# EDGE register map
Registers are 32-bit, access not given, reset 0x11 unless marked. A register's access mark holds for its fields unless they carry their own. Offsets are from the block's base; lines under a group give offsets from that group; [hi:lo] are bit positions; {n}, {i} and the like mark numbered series; 'fields as' and 'values as' point back to an identical list; <NAME> marks a mode.

## Memory map
0x40021000 CTRL size 0x400 — Control & status block
0x40022000 CTRL2 size 0x400
0x40030000 LOOP1
0x40031000 LOOP2

## CTRL — Control & status block
Base 0x40021000
Same registers: CTRL2 0x40022000
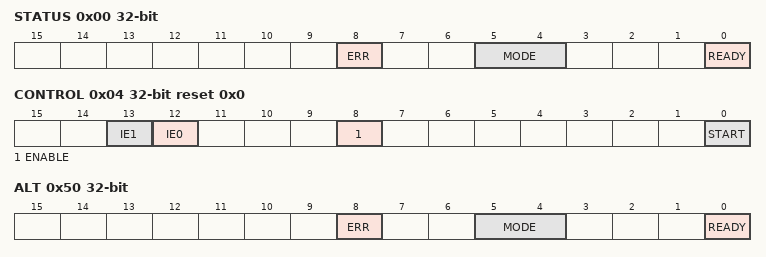
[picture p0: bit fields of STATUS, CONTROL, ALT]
0x00 STATUS ro
  [8] ERR
  [5:4] MODE
    0=Idle; 2=Busy; 0b1x=Any
  [0] READY
0x04 CONTROL reset 0x0
  [n+12] IE{n} (n=0..1), [8] ENABLE, [0] START
{0x10+0x10*i} CH[{i}] (i=0..1) group
  0x00 CR
  0x04 DR 16-bit
0x40 DATA{x} (x=A,B,C; step 0x4)
0x50 ALT ro — Status
  [8] ERR
  [5:4] MODE
    0=Idle; 2=Busy; 0b1x=Any
  [0] READY
0x54 BYTE 8-bit

## Notices in the file
SPDX-License-Identifier: Apache-2.0
